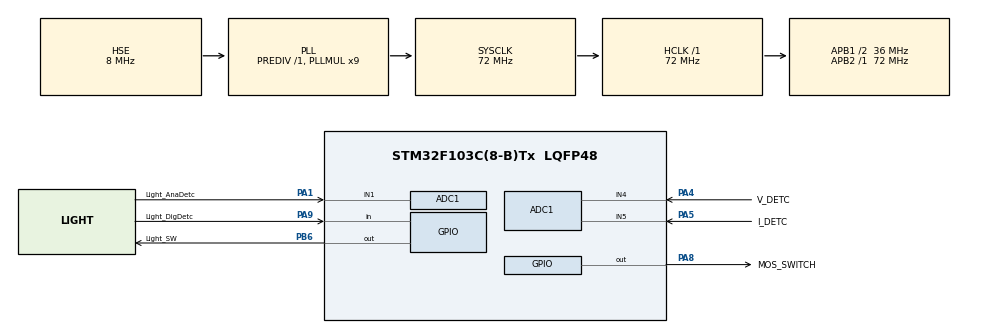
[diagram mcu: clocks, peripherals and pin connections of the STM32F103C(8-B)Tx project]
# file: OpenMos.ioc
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ADC1.Channel-0\#ChannelRegularConversion=ADC_CHANNEL_1
ADC1.Channel-1\#ChannelRegularConversion=ADC_CHANNEL_4
ADC1.Channel-2\#ChannelRegularConversion=ADC_CHANNEL_5
ADC1.Channel-4\#ChannelRegularConversion=ADC_CHANNEL_VREFINT
ADC1.ContinuousConvMode=ENABLE
ADC1.NbrOfConversion=4
ADC1.NbrOfConversionFlag=1
ADC1.Rank-0\#ChannelRegularConversion=1
ADC1.Rank-1\#ChannelRegularConversion=2
ADC1.Rank-2\#ChannelRegularConversion=3
ADC1.Rank-4\#ChannelRegularConversion=4
ADC1.SamplingTime-0\#ChannelRegularConversion=ADC_SAMPLETIME_41CYCLES_5
ADC1.SamplingTime-1\#ChannelRegularConversion=ADC_SAMPLETIME_41CYCLES_5
ADC1.SamplingTime-2\#ChannelRegularConversion=ADC_SAMPLETIME_41CYCLES_5
ADC1.SamplingTime-4\#ChannelRegularConversion=ADC_SAMPLETIME_71CYCLES_5
ADC1.master=1
Dma.ADC1.0.Direction=DMA_PERIPH_TO_MEMORY
Dma.ADC1.0.Instance=DMA1_Channel1
Dma.ADC1.0.MemDataAlignment=DMA_MDATAALIGN_HALFWORD
Dma.ADC1.0.MemInc=DMA_MINC_ENABLE
Dma.ADC1.0.Mode=DMA_CIRCULAR
Dma.ADC1.0.PeriphDataAlignment=DMA_PDATAALIGN_HALFWORD
Dma.ADC1.0.PeriphInc=DMA_PINC_DISABLE
Dma.ADC1.0.Priority=DMA_PRIORITY_LOW
Dma.Request0=ADC1
Mcu.Family=STM32F1
Mcu.Name=STM32F103C(8-B)Tx
Mcu.Package=LQFP48
NVIC.DMA1_Channel1_IRQn=true\:0\:0\:false\:false\:true\:false\:true\:true
NVIC.PriorityGroup=NVIC_PRIORITYGROUP_4
PA1.GPIO_Label=Light_AnaDetc
PA1.Signal=ADCx_IN1
PA13.Mode=Serial_Wire
PA13.Signal=SYS_JTMS-SWDIO
PA14.Mode=Serial_Wire
PA14.Signal=SYS_JTCK-SWCLK
PA4.GPIO_Label=V_DETC
PA4.Signal=ADCx_IN4
PA5.GPIO_Label=I_DETC
PA5.Signal=ADCx_IN5
PA8.GPIO_Label=MOS_SWITCH
PA8.Signal=GPIO_Output
PA9.GPIO_Label=Light_DigDetc
PA9.Signal=GPIO_Input
PB6.GPIO_Label=Light_SW
PB6.Signal=GPIO_Output
PD0-OSC_IN.Mode=HSE-External-Oscillator
PD0-OSC_IN.Signal=RCC_OSC_IN
PD1-OSC_OUT.Mode=HSE-External-Oscillator
PD1-OSC_OUT.Signal=RCC_OSC_OUT
ProjectManager.HeapSize=0x200
ProjectManager.StackSize=0x400
ProjectManager.TargetToolchain=CMake
RCC.ADCPresc=RCC_ADCPCLK2_DIV6
RCC.AHBFreq_Value=72000000
RCC.APB1CLKDivider=RCC_HCLK_DIV2
RCC.APB1Freq_Value=36000000
RCC.APB1TimFreq_Value=72000000
RCC.APB2Freq_Value=72000000
RCC.APB2TimFreq_Value=72000000
RCC.HCLKFreq_Value=72000000
RCC.PLLMUL=RCC_PLL_MUL9
RCC.PLLSourceVirtual=RCC_PLLSOURCE_HSE
RCC.SYSCLKFreq_VALUE=72000000
RCC.SYSCLKSource=RCC_SYSCLKSOURCE_PLLCLK
RCC.USBFreq_Value=72000000
SH.ADCx_IN1.0=ADC1_IN1,IN1
SH.ADCx_IN4.0=ADC1_IN4,IN4
SH.ADCx_IN5.0=ADC1_IN5,IN5
VP_ADC1_Vref_Input.Mode=IN-Vrefint
board=custom

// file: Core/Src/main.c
/* USER CODE BEGIN Header */
/**
 ******************************************************************************
 * @file           : main.c
 * @brief          : Main program body
 ******************************************************************************
 * @attention
 *
 * Copyright (c) 2025 STMicroelectronics.
 * All rights reserved.
 *
 * This software is licensed under terms that can be found in the LICENSE file
 * in the root directory of this software component.
 * If no LICENSE file comes with this software, it is provided AS-IS.
 *
 ******************************************************************************
 */
/* USER CODE END Header */
#include "main.h"
#include "adc.h"
#include "dma.h"
#include "gpio.h"

/* USER CODE BEGIN Includes */

/**
 * User Include
 */
#include "Function.h"
/*End User*/

/* USER CODE END Includes */

/* USER CODE BEGIN PV */

/**
 * User Define variables
 */
extern ADC_Sample my_adc_value;
extern int MOS_belief;
extern float L_rvAver;
extern MOS_State Mos;

// extern low_pass_filter_t  low_pass_filter1;  //定义滤波器
// extern low_pass_filter_t  low_pass_filter2;  //定义滤波器
// extern low_pass_filter_t  low_pass_filter3;  //定义滤波器

/* USER CODE END PV */

void SystemClock_Config(void);

int main(void)
{

  /* MCU Configuration--------------------------------------------------------*/

  /* Reset of all peripherals, Initializes the Flash interface and the Systick. */
  HAL_Init();

  /* Configure the system clock */
  SystemClock_Config();

  /* Initialize all configured peripherals */
  MX_GPIO_Init();
  MX_DMA_Init();
  MX_ADC1_Init();
  /* USER CODE BEGIN 2 */

  /**
   * User Function
   */
  // 滤波器初始化
  // Init_lowPass_alpha(&low_pass_filter1, 0.1f, 1);
  // Init_lowPass_alpha(&low_pass_filter2, 0.1f, 1);
  // Init_lowPass_alpha(&low_pass_filter3, 0.1f, 1);//低通滤波好像有问题，容易导致值溢出

  // 关闭白灯
  HAL_GPIO_WritePin(Light_SW_GPIO_Port, Light_SW_Pin, GPIO_PIN_SET);
  HAL_Delay(500); // 缓启动，等待上电

  // 开启ADC采样
  ADC_Sample_Start(&hadc1);

  /*End User*/

  /* USER CODE END 2 */

  /* Infinite loop */
  /* USER CODE BEGIN WHILE */
  while (1)
  {
    /**
     * User Function
     */

    // 开启ADC转换
    ADC_Data_Trans(&my_adc_value);

    // 判断MOS是否打开
    Open_Mos(&Mos);

    /*End User*/

    /* USER CODE END WHILE */

  }
}

void SystemClock_Config(void)
{
  RCC_OscInitTypeDef RCC_OscInitStruct = {0};
  RCC_ClkInitTypeDef RCC_ClkInitStruct = {0};
  RCC_PeriphCLKInitTypeDef PeriphClkInit = {0};

  /** Initializes the RCC Oscillators according to the specified parameters
   * in the RCC_OscInitTypeDef structure.
   */
  RCC_OscInitStruct.OscillatorType = RCC_OSCILLATORTYPE_HSE;
  RCC_OscInitStruct.HSEState = RCC_HSE_ON;
  RCC_OscInitStruct.HSEPredivValue = RCC_HSE_PREDIV_DIV1;
  RCC_OscInitStruct.HSIState = RCC_HSI_ON;
  RCC_OscInitStruct.PLL.PLLState = RCC_PLL_ON;
  RCC_OscInitStruct.PLL.PLLSource = RCC_PLLSOURCE_HSE;
  RCC_OscInitStruct.PLL.PLLMUL = RCC_PLL_MUL9;
  if (HAL_RCC_OscConfig(&RCC_OscInitStruct) != HAL_OK)
  {
    Error_Handler();
  }

  /** Initializes the CPU, AHB and APB buses clocks
   */
  RCC_ClkInitStruct.ClockType = RCC_CLOCKTYPE_HCLK | RCC_CLOCKTYPE_SYSCLK | RCC_CLOCKTYPE_PCLK1 | RCC_CLOCKTYPE_PCLK2;
  RCC_ClkInitStruct.SYSCLKSource = RCC_SYSCLKSOURCE_PLLCLK;
  RCC_ClkInitStruct.AHBCLKDivider = RCC_SYSCLK_DIV1;
  RCC_ClkInitStruct.APB1CLKDivider = RCC_HCLK_DIV2;
  RCC_ClkInitStruct.APB2CLKDivider = RCC_HCLK_DIV1;

  if (HAL_RCC_ClockConfig(&RCC_ClkInitStruct, FLASH_LATENCY_2) != HAL_OK)
  {
    Error_Handler();
  }
  PeriphClkInit.PeriphClockSelection = RCC_PERIPHCLK_ADC;
  PeriphClkInit.AdcClockSelection = RCC_ADCPCLK2_DIV6;
  if (HAL_RCCEx_PeriphCLKConfig(&PeriphClkInit) != HAL_OK)
  {
    Error_Handler();
  }
}

void Error_Handler(void)
{
  __disable_irq();
  while (1)
  {
  }
}
